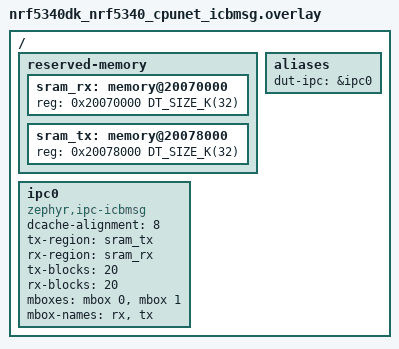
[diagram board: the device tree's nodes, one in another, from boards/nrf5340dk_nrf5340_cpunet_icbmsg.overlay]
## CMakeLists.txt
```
#
# Copyright (c) 2025 Nordic Semiconductor ASA
#
# SPDX-License-Identifier: Apache-2.0
#

cmake_minimum_required(VERSION 3.20.0)

find_package(Zephyr REQUIRED HINTS $ENV{ZEPHYR_BASE})
project(ipc_service_api_remote)

target_include_directories(app PRIVATE ${CMAKE_CURRENT_SOURCE_DIR}/../common)
target_sources(app PRIVATE src/remote.c)
```

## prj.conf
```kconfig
CONFIG_IPC_SERVICE=y
CONFIG_LOG=y
#CONFIG_LOG_MODE_MINIMAL=y
CONFIG_MBOX=y
```

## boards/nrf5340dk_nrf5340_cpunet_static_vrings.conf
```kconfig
CONFIG_MBOX=y
CONFIG_HEAP_MEM_POOL_SIZE=4096
CONFIG_OPENAMP=y
CONFIG_OPENAMP_MASTER=n
```

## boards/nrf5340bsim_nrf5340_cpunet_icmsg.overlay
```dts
/*
 * SPDX-License-Identifier: Apache-2.0
 */

#include "nrf5340dk_nrf5340_cpunet_icmsg.overlay"
```

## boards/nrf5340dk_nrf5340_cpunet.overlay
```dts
/*
 * Copyright (c) 2025 Nordic Semiconductor ASA
 *
 * SPDX-License-Identifier: Apache-2.0
 */

#include "nrf5340dk_nrf5340_cpunet_common.dtsi"
```

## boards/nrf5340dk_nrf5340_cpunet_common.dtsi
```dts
/*
 * Copyright (c) 2025 Nordic Semiconductor ASA
 *
 * SPDX-License-Identifier: Apache-2.0
 */

/delete-node/ &ipc0;
/delete-node/ &sram0_shared;

/ {
	chosen {
		/delete-property/ zephyr,ipc_shm;
	};
};
```

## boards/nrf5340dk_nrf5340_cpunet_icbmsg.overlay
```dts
/*
 * Copyright (c) 2025 Nordic Semiconductor ASA
 *
 * SPDX-License-Identifier: Apache-2.0
 */

#include "nrf5340dk_nrf5340_cpunet_common.dtsi"

/ {
	reserved-memory {
		#address-cells = <1>;
		#size-cells = <1>;
		ranges;

		sram_rx: memory@20070000 {
			reg = <0x20070000 DT_SIZE_K(32)>;
		};

		sram_tx: memory@20078000 {
			reg = <0x20078000 DT_SIZE_K(32)>;
		};
	};

	ipc0: ipc0 {
		compatible = "zephyr,ipc-icbmsg";
		dcache-alignment = <8>;
		tx-region = <&sram_tx>;
		rx-region = <&sram_rx>;
		tx-blocks = <20>;
		rx-blocks = <20>;
		mboxes = <&mbox 0>, <&mbox 1>;
		mbox-names = "rx", "tx";
		status = "okay";
	};

	aliases {
		dut-ipc = &ipc0;
	};
};
```

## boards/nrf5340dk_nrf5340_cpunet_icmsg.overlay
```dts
/*
 * Copyright (c) 2025 Nordic Semiconductor ASA
 *
 * SPDX-License-Identifier: Apache-2.0
 */

#include "nrf5340dk_nrf5340_cpunet_common.dtsi"

/ {
	reserved-memory {
		#address-cells = <1>;
		#size-cells = <1>;
		ranges;

		sram_rx: memory@20070000 {
			reg = <0x20070000 DT_SIZE_K(32)>;
		};

		sram_tx: memory@20078000 {
			reg = <0x20078000 DT_SIZE_K(32)>;
		};
	};

	ipc0: ipc0 {
		compatible = "zephyr,ipc-icmsg";
		dcache-alignment = <8>;
		tx-region = <&sram_tx>;
		rx-region = <&sram_rx>;
		mboxes = <&mbox 0>, <&mbox 1>;
		mbox-names = "rx", "tx";
		status = "okay";
	};

	aliases {
		dut-ipc = &ipc0;
	};
};
```

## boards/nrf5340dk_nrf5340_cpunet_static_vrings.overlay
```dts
/*
 * Copyright (c) 2025 Nordic Semiconductor ASA
 *
 * SPDX-License-Identifier: Apache-2.0
 */

#include "nrf5340dk_nrf5340_cpunet_common.dtsi"
#include <zephyr/dt-bindings/ipc_service/static_vrings.h>

/ {
	reserved-memory {
		#address-cells = <1>;
		#size-cells = <1>;

		sram_ipc0: memory@20070000 {
			reg = <0x20070000 DT_SIZE_K(8)>;
		};
	};

	ipc0: ipc0 {
		compatible = "zephyr,ipc-openamp-static-vrings";
		memory-region = <&sram_ipc0>;
		mboxes = <&mbox 0>, <&mbox 1>;
		mbox-names = "rx", "tx";
		role = "remote";
		zephyr,buffer-size = <128>;
		status = "okay";
	};

	aliases {
		dut-ipc = &ipc0;
	};
};
```

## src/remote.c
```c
/*
 * Copyright (c) 2025 Nordic Semiconductor ASA
 *
 * SPDX-License-Identifier: Apache-2.0
 */

#include <string.h>

#include <zephyr/kernel.h>
#include <zephyr/device.h>
#include <zephyr/ipc/ipc_service.h>

#include <api_test.h>

#include <zephyr/logging/log.h>
LOG_MODULE_REGISTER(remote, LOG_LEVEL_INF);

static const struct device *ipc0_instance = DEVICE_DT_GET(DT_ALIAS(dut_ipc));
static volatile bool ipc0_bounded;
static volatile bool close_after_unbound;
K_SEM_DEFINE(bound_sem, 0, 1);

static struct ipc_ept ep;

static struct ipc_ept_cfg ep_cfg;

static void remote_deregister_work_handler(struct k_work *work)
{
	int ret;

	ARG_UNUSED(work);

	ret = ipc_service_deregister_endpoint(&ep);
	if (ret < 0 && ret != -ENOENT) {
		LOG_ERR("ipc_service_deregister_endpoint() failed: %d", ret);
	}

	k_msleep(10);

	ret = ipc_service_register_endpoint(ipc0_instance, &ep, &ep_cfg);
	if (ret < 0) {
		LOG_ERR("ipc_service_register_endpoint() after deregister failed: %d", ret);
	}
}

static K_WORK_DELAYABLE_DEFINE(remote_deregister_work, remote_deregister_work_handler);

static void reopen_ipc_work_handler(struct k_work *work)
{
	int ret;

	ARG_UNUSED(work);


	ret = ipc_service_close_instance(ipc0_instance);
	if (ret < 0) {
		LOG_ERR("ipc_service_close_instance() after unbound failed: %d", ret);
	}

	k_msleep(1);

	ret = ipc_service_open_instance(ipc0_instance);
	if (ret < 0 && ret != -EALREADY) {
		LOG_ERR("ipc_service_open_instance() after unbound failed: %d", ret);
		return;
	}

	ret = ipc_service_register_endpoint(ipc0_instance, &ep, &ep_cfg);
	if (ret < 0) {
		LOG_ERR("ipc_service_register_endpoint() after unbound failed: %d", ret);
	}
}

static K_WORK_DELAYABLE_DEFINE(reopen_ipc_work, reopen_ipc_work_handler);

static void ep_bound(void *priv)
{
	ipc0_bounded = true;
	k_sem_give(&bound_sem);
	LOG_INF("Endpoint bound");
}

static void ep_unbound(void *priv)
{
	int ret;

	ipc0_bounded = false;
	k_sem_reset(&bound_sem);
	LOG_INF("Endpoint unbound");

	if (close_after_unbound) {
		close_after_unbound = false;

		ret = ipc_service_deregister_endpoint(&ep);
		LOG_ERR("ipc_service_deregister_endpoint() after unbound failed: %d", ret);
		if (ret < 0 && ret != -ENOENT) {
			LOG_ERR("ipc_service_deregister_endpoint() after unbound failed: %d", ret);
		}

		ret = k_work_schedule(&reopen_ipc_work, K_MSEC(1));
		if (ret < 0) {
			LOG_ERR("reopen_ipc_work schedule failed: %d", ret);
		}
		return;
	}

	/* By default attempt to reregister the endpoint. */
	ret = k_work_schedule(&remote_deregister_work, K_NO_WAIT);
	if (ret < 0) {
		LOG_ERR("remote_deregister_work schedule failed: %d", ret);
	}
}

static void ep_error(const char *message, void *priv)
{
	LOG_ERR("Endpoint error: %s", message);
}

static void ep_recv(const void *data, size_t len, void *priv)
{
	const struct api_test_msg *msg = data;
	struct ipc_ept *ept = priv;
	struct api_test_msg rsp;
	int ret;

	if (len < sizeof(msg->cmd)) {
		LOG_ERR("Unexpected message size: %u", len);
		return;
	}

	switch (msg->cmd) {
	case API_TEST_CMD_PING:
		rsp.cmd = API_TEST_CMD_PONG;
		memset(rsp.data, 0, sizeof(rsp.data));
		ret = ipc_service_send(ept, &rsp, sizeof(rsp));
		if (ret < 0) {
			LOG_ERR("PONG send failed: %d", ret);
		}
		break;
	case API_TEST_CMD_ECHO:
		if (len < sizeof(struct api_test_msg)) {
			LOG_ERR("ECHO message too short: %u", len);
			break;
		}
		rsp.cmd = API_TEST_CMD_ECHO_RSP;
		memcpy(rsp.data, msg->data, sizeof(rsp.data));
		ret = ipc_service_send(ept, &rsp, sizeof(rsp));
		if (ret < 0) {
			LOG_ERR("ECHO_RSP send failed: %d", ret);
		}
		break;
	case API_TEST_CMD_PUSH:
		if (len < sizeof(struct api_test_msg)) {
			LOG_ERR("PUSH message too short: %u", len);
			break;
		}
		ret = ipc_service_send(ept, msg, sizeof(*msg));
		if (ret < 0) {
			LOG_ERR("PUSH response send failed: %d", ret);
		}
		break;
	case API_TEST_CMD_HOLD_RX:
		if (len < sizeof(struct api_test_msg)) {
			LOG_ERR("HOLD_RX message too short: %u", len);
			break;
		}
		rsp.cmd = API_TEST_CMD_HOLD_RX_RSP;
		memcpy(rsp.data, msg->data, sizeof(rsp.data));
		ret = ipc_service_send(ept, &rsp, sizeof(rsp));
		if (ret < 0) {
			LOG_ERR("HOLD_RX_RSP send failed: %d", ret);
		}
		break;
	case API_TEST_CMD_CLOSE_AFTER_UNBOUND:
		close_after_unbound = true;
		break;
	case API_TEST_CMD_DEREGISTER:
		ret = k_work_schedule(&remote_deregister_work, K_NO_WAIT);
		if (ret < 0) {
			LOG_ERR("remote_deregister_work schedule failed: %d", ret);
		}
		break;
	default:
		LOG_ERR("Unhandled command: %u", msg->cmd);
		break;
	}
}

int main(void)
{
	int ret;

	ep_cfg.name = "ep0";
	ep_cfg.cb.bound = ep_bound;
	ep_cfg.cb.unbound = ep_unbound;
	ep_cfg.cb.received = ep_recv;
	ep_cfg.cb.error = ep_error;
	ep_cfg.priv = &ep;

	ret = ipc_service_open_instance(ipc0_instance);
	if (ret < 0 && ret != -EALREADY) {
		LOG_ERR("ipc_service_open_instance() failed: %d", ret);
		return ret;
	}

	ret = ipc_service_register_endpoint(ipc0_instance, &ep, &ep_cfg);
	if (ret < 0) {
		LOG_ERR("ipc_service_register_endpoint() failed: %d", ret);
		return ret;
	}

	k_sem_take(&bound_sem, K_FOREVER);

	LOG_INF("IPC service API remote ready");

	k_sleep(K_FOREVER);
	return 0;
}
```
